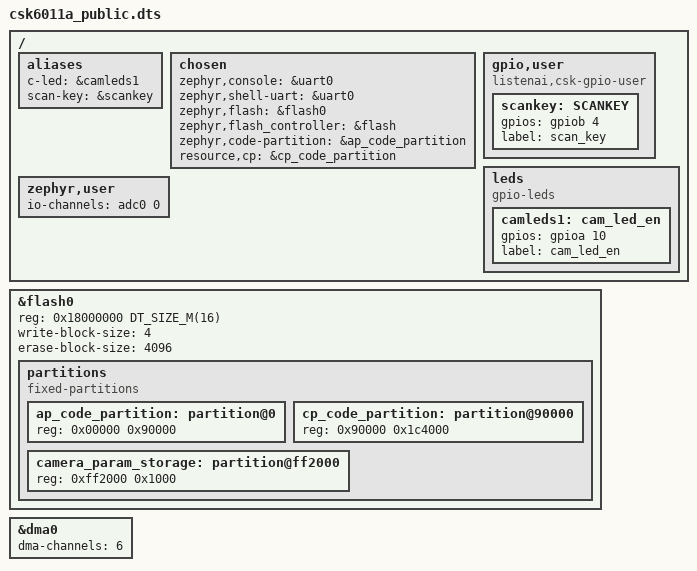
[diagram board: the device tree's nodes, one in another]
/dts-v1/;
#include <csk/csk6011a.dtsi>
#include <zephyr/dt-bindings/pwm/pwm.h>
#include <zephyr/dt-bindings/gpio/gpio.h>
#include "csk6011a_public.dtsi"
#include "csk6011a_public_pinctrl.dtsi"

/ {
        aliases {
                // led0 = &board_led_2;
                c-led = &camleds1;
                scan-key = &scankey;
        };
        
        chosen {
                zephyr,console = &uart0;
                zephyr,shell-uart = &uart0;
                zephyr,flash = &flash0;
                zephyr,flash_controller = &flash;
                zephyr,code-partition = &ap_code_partition;
                resource,cp = &cp_code_partition;
                // resource,ocr_cutline = &res_ocr_cutline_partition;
                // resource,xtts_front = &xtts_front_partition;
                // resource,xtts_role = &xtts_role_partition;
                // resource,trans_dict = &res_trans_dict_partition;
                // resource,trans_encode = &res_trans_encoder_partition;
                // resource,trans_db = &res_trans_db_partition;
        };

        gpio,user {
                compatible = "listenai,csk-gpio-user";
                scankey: SCANKEY {
                        gpios = <&gpiob 4 0>;
                        label = "scan_key";
                };
        };

        leds {
                compatible = "gpio-leds";
                camleds1: cam_led_en  {
                        gpios = <&gpioa 10 0>;
                        label = "cam_led_en";
                };

        };
        zephyr,user {
                io-channels = <&adc0 0>;
        };

};

&flash0 {
        reg = <0x18000000 DT_SIZE_M(16)>;
        write-block-size = <4>;
        erase-block-size = <4096>;
        partitions {
                compatible = "fixed-partitions";
                #address-cells = <1>;
                #size-cells = <1>;
                ap_code_partition: partition@0 {
                        reg = <0x00000 0x90000>;
                };
                cp_code_partition: partition@90000 {
                        reg = <0x90000 0x1c4000>;
                };
                camera_param_storage: partition@ff2000 {
                        reg = <0xff2000 0x1000>;
                };
        };
};

&dma0 {
        dma-channels = <6>;
        status = "okay";
};
